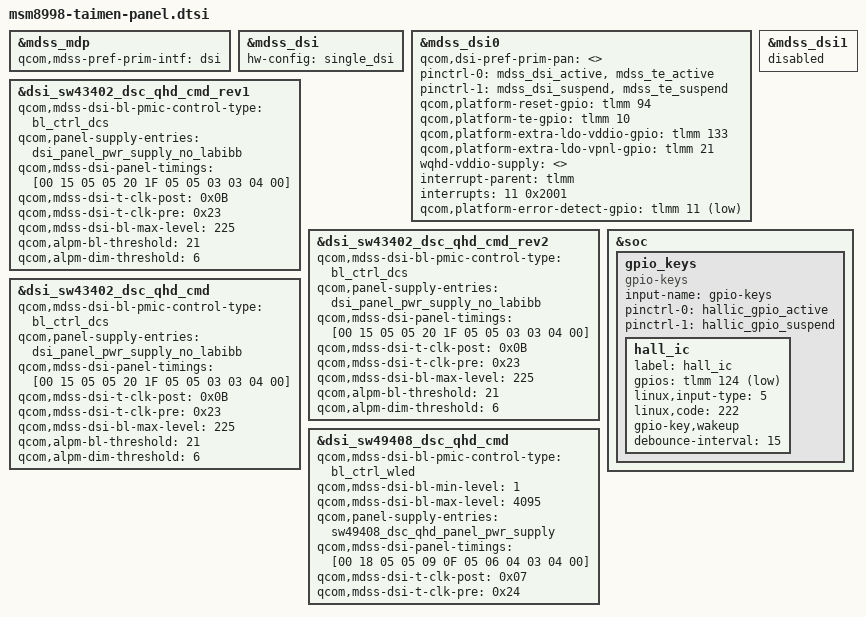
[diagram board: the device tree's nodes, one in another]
/* Copyright (c) 2017, The Linux Foundation. All rights reserved.
 *
 * This program is free software; you can redistribute it and/or modify
 * it under the terms of the GNU General Public License version 2 and
 * only version 2 as published by the Free Software Foundation.
 *
 * This program is distributed in the hope that it will be useful,
 * but WITHOUT ANY WARRANTY; without even the implied warranty of
 * MERCHANTABILITY or FITNESS FOR A PARTICULAR PURPOSE.  See the
 * GNU General Public License for more details.
 */

#include "dsi-panel-sw43402-dsc-qhd-cmd-rev1.dtsi"
#include "dsi-panel-sw43402-dsc-qhd-cmd-rev2.dtsi"
#include "dsi-panel-sw43402-dsc-qhd-cmd.dtsi"
#include "dsi-panel-sw49408-dsc-qhd-cmd.dtsi"

&mdss_mdp {
	qcom,mdss-pref-prim-intf = "dsi";
};

&mdss_dsi {
	hw-config = "single_dsi";
};

&mdss_dsi0 {
	qcom,dsi-pref-prim-pan = <>;
	pinctrl-names = "mdss_default", "mdss_sleep";
	pinctrl-0 = <&mdss_dsi_active &mdss_te_active>;
	pinctrl-1 = <&mdss_dsi_suspend &mdss_te_suspend>;
	qcom,platform-reset-gpio = <&tlmm 94 0>;
	qcom,platform-te-gpio = <&tlmm 10 0>;
	qcom,platform-extra-ldo-vddio-gpio = <&tlmm 133 0>;
	qcom,platform-extra-ldo-vpnl-gpio = <&tlmm 21 0>;
	wqhd-vddio-supply = <>;
	interrupt-parent = <&tlmm>;
	interrupts = <11 0x2001>; /*IRQF_ONESHOT | IRQF_TRIGGER_RISING*/
	qcom,platform-error-detect-gpio =  <&tlmm 11 0x2001>; /* IRQF_ONESHOT | IRQF_TRIGGER_RISING */
};

&mdss_dsi1 {
	status = "disabled";
};

&dsi_sw43402_dsc_qhd_cmd_rev1 {
	qcom,mdss-dsi-bl-pmic-control-type = "bl_ctrl_dcs";
	/* qcom,cont-splash-enabled; */
	qcom,panel-supply-entries = <&dsi_panel_pwr_supply_no_labibb>;
	qcom,mdss-dsi-panel-timings = [00 15 05 05 20 1F 05 05 03 03 04 00];
	qcom,mdss-dsi-t-clk-post = <0x0B>;
	qcom,mdss-dsi-t-clk-pre = <0x23>;
	qcom,mdss-dsi-bl-max-level = <225>;
	qcom,alpm-bl-threshold = <21>;
	qcom,alpm-dim-threshold = <6>;
};

&dsi_sw43402_dsc_qhd_cmd_rev2 {
	qcom,mdss-dsi-bl-pmic-control-type = "bl_ctrl_dcs";
	/* qcom,cont-splash-enabled; */
	qcom,panel-supply-entries = <&dsi_panel_pwr_supply_no_labibb>;
	qcom,mdss-dsi-panel-timings = [00 15 05 05 20 1F 05 05 03 03 04 00];
	qcom,mdss-dsi-t-clk-post = <0x0B>;
	qcom,mdss-dsi-t-clk-pre = <0x23>;
	qcom,mdss-dsi-bl-max-level = <225>;
	qcom,alpm-bl-threshold = <21>;
	qcom,alpm-dim-threshold = <6>;
};

&dsi_sw43402_dsc_qhd_cmd {
	qcom,mdss-dsi-bl-pmic-control-type = "bl_ctrl_dcs";
	/* qcom,cont-splash-enabled; */
	qcom,panel-supply-entries = <&dsi_panel_pwr_supply_no_labibb>;
	qcom,mdss-dsi-panel-timings = [00 15 05 05 20 1F 05 05 03 03 04 00];
	qcom,mdss-dsi-t-clk-post = <0x0B>;
	qcom,mdss-dsi-t-clk-pre = <0x23>;
	qcom,mdss-dsi-bl-max-level = <225>;
	qcom,alpm-bl-threshold = <21>;
	qcom,alpm-dim-threshold = <6>;
};

&dsi_sw49408_dsc_qhd_cmd {
	qcom,mdss-dsi-bl-pmic-control-type = "bl_ctrl_wled";
	qcom,mdss-dsi-bl-min-level = <1>;
	qcom,mdss-dsi-bl-max-level = <4095>;
	qcom,panel-supply-entries = <&sw49408_dsc_qhd_panel_pwr_supply>;

	qcom,mdss-dsi-panel-timings = [00 18 05 05 09 0F 05 06 04 03 04 00];
	qcom,mdss-dsi-t-clk-post = <0x07>;
	qcom,mdss-dsi-t-clk-pre = <0x24>;
};
/* End of overriding parameters in msm8998-mdss-panel.dtsi */

/* Hall IC */
&soc {
	gpio_keys {
		compatible = "gpio-keys";
		input-name = "gpio-keys";

		pinctrl-names = "tlmm_gpio_key_active","tlmm_gpio_key_suspend";
		pinctrl-0 = <&hallic_gpio_active>;
		pinctrl-1 = <&hallic_gpio_suspend>;

		hall_ic {
			label = "hall_ic";
			gpios = <&tlmm 124 0x1>;
			linux,input-type = <5>;
			linux,code = <222>;
			gpio-key,wakeup;
			debounce-interval = <15>;
		};
	};
};
